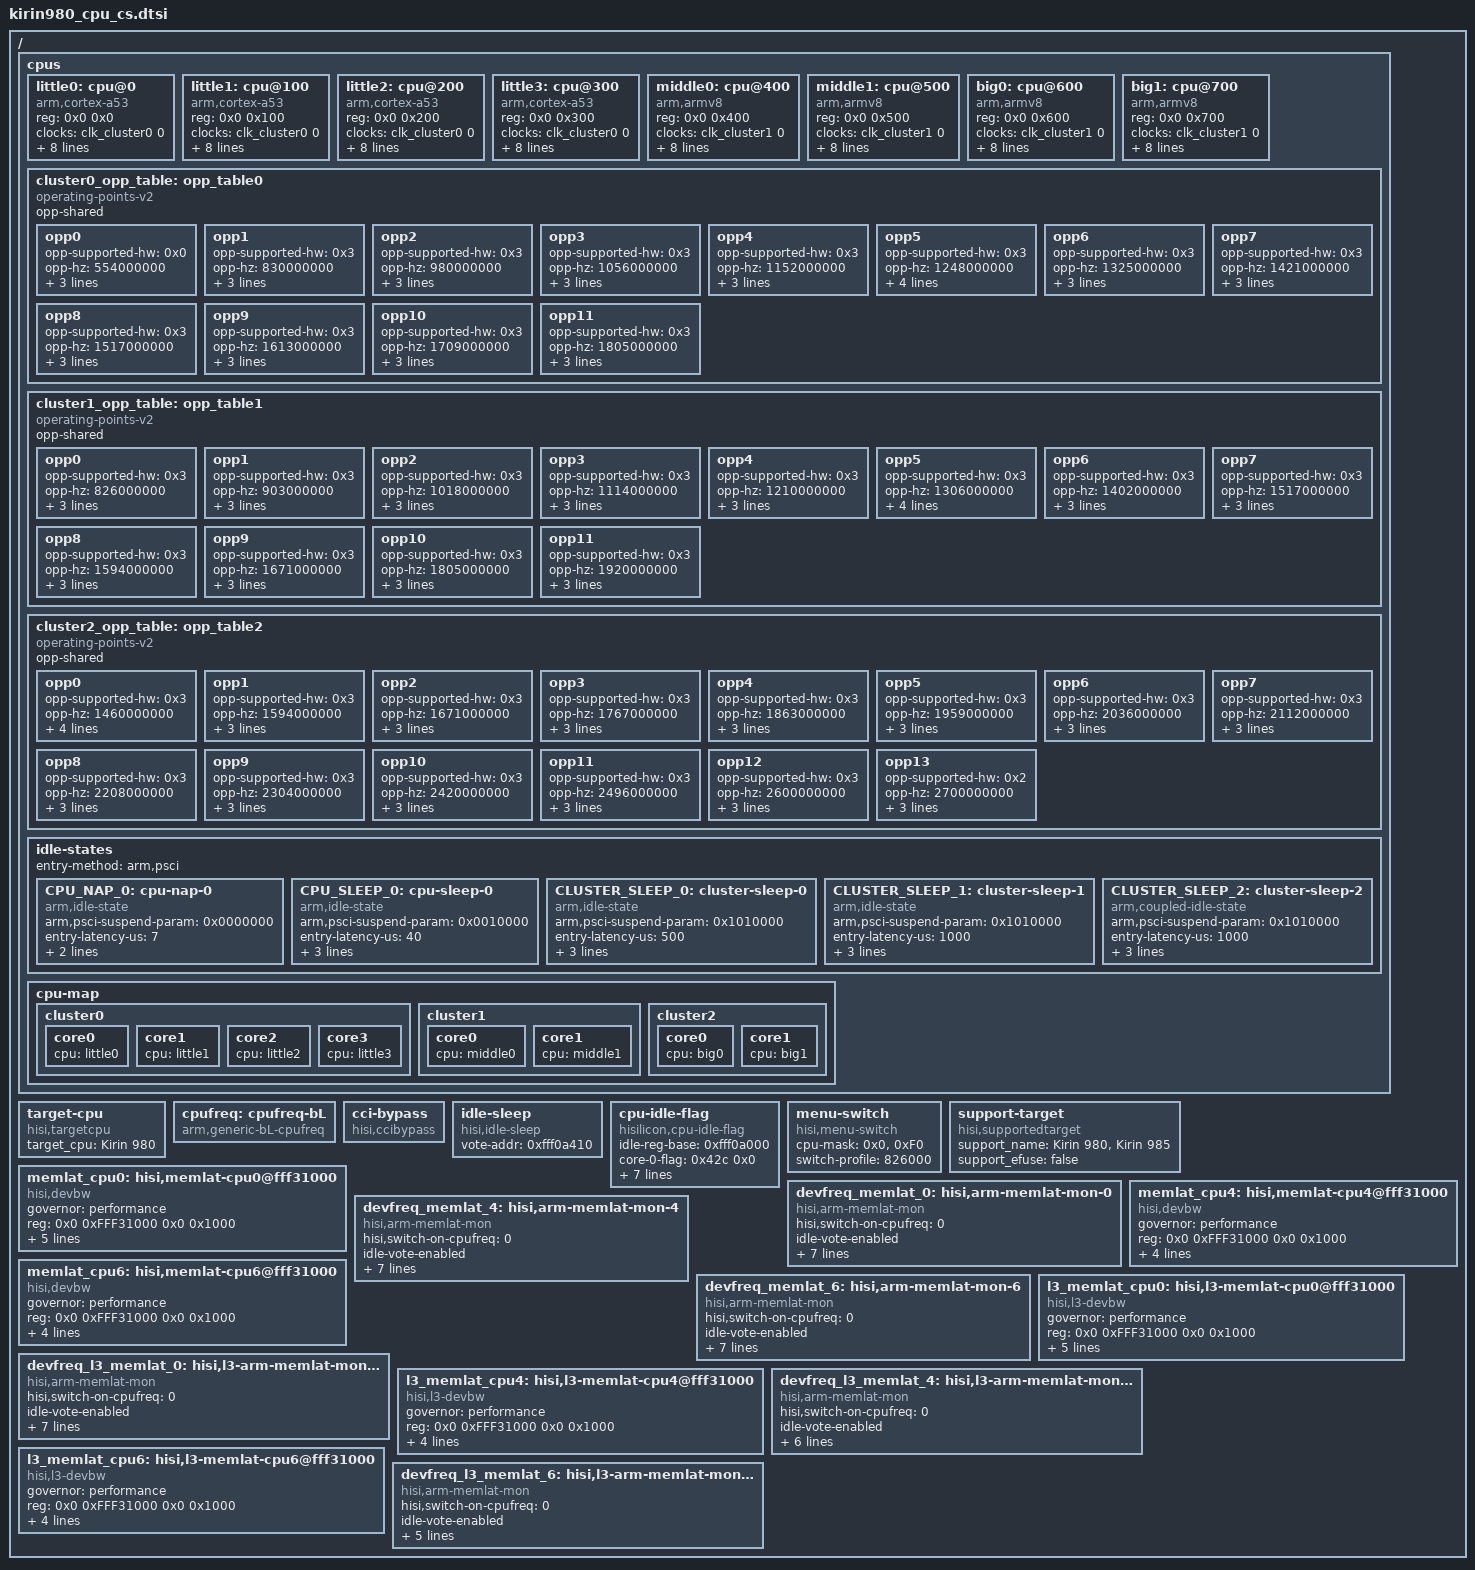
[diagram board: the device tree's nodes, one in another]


/{
	cpus {
		#address-cells = <2>;
		#size-cells = <0>;

		little0: cpu@0 {
			device_type = "cpu";
			compatible = "arm,cortex-a53", "arm,armv8";
			reg = <0x0 0x0>;
			clocks = <&clk_cluster0 0>;
			clock-names = "cpu-cluster.0";
			freq-vote-channel = "little-freq", "vote-src-1";
			enable-method = "psci";
			clock-frequency = <0>;
			clock-latency = <0>;
			cpu-idle-states = <&CPU_SLEEP_0 &CLUSTER_SLEEP_0>;
			operating-points-v2 = <&cluster0_opp_table>;
			sched-energy-costs = <&CPU_COST_Ananke &CLUSTER_COST_Ananke>;
		};
		little1:cpu@100 {
			device_type = "cpu";
			compatible = "arm,cortex-a53", "arm,armv8";
			reg = <0x0 0x100>;
			clocks = <&clk_cluster0 0>;
			clock-names = "cpu-cluster.0";
			freq-vote-channel = "little-freq", "vote-src-1";
			enable-method = "psci";
			clock-frequency = <0>;
			clock-latency = <0>;
			cpu-idle-states = <&CPU_SLEEP_0 &CLUSTER_SLEEP_0>;
			operating-points-v2 = <&cluster0_opp_table>;
			sched-energy-costs = <&CPU_COST_Ananke &CLUSTER_COST_Ananke>;
		};
		little2:cpu@200 {
			device_type = "cpu";
			compatible = "arm,cortex-a53", "arm,armv8";
			reg = <0x0 0x200>;
			clocks = <&clk_cluster0 0>;
			clock-names = "cpu-cluster.0";
			freq-vote-channel = "little-freq", "vote-src-1";
			enable-method = "psci";
			clock-frequency = <0>;
			clock-latency = <0>;
			cpu-idle-states = <&CPU_SLEEP_0 &CLUSTER_SLEEP_0>;
			operating-points-v2 = <&cluster0_opp_table>;
			sched-energy-costs = <&CPU_COST_Ananke &CLUSTER_COST_Ananke>;
		};
		little3:cpu@300 {
			device_type = "cpu";
			compatible = "arm,cortex-a53", "arm,armv8";
			reg = <0x0 0x300>;
			clocks = <&clk_cluster0 0>;
			clock-names = "cpu-cluster.0";
			freq-vote-channel = "little-freq", "vote-src-1";
			enable-method = "psci";
			clock-frequency = <0>;
			clock-latency = <0>;
			cpu-idle-states = <&CPU_SLEEP_0 &CLUSTER_SLEEP_0>;
			operating-points-v2 = <&cluster0_opp_table>;
			sched-energy-costs = <&CPU_COST_Ananke &CLUSTER_COST_Ananke>;
		};


		middle0:cpu@400 {
			device_type = "cpu";
			compatible = "arm,armv8";
			reg = <0x0 0x400>;
			clocks = <&clk_cluster1 0>;
			clock-names = "cpu-cluster.1";
			freq-vote-channel = "middle-freq", "vote-src-1";
			enable-method = "psci";
			clock-frequency = <0>;
			clock-latency = <0>;
			cpu-idle-states = <&CPU_SLEEP_0 &CLUSTER_SLEEP_1>;
			operating-points-v2 = <&cluster1_opp_table>;
			sched-energy-costs = <&CPU_COST_Enyo_M &CLUSTER_COST_Enyo_M>;
		};
		middle1:cpu@500 {
			device_type = "cpu";
			compatible = "arm,armv8";
			reg = <0x0 0x500>;
			clocks = <&clk_cluster1 0>;
			clock-names = "cpu-cluster.1";
			freq-vote-channel = "middle-freq", "vote-src-1";
			clock-frequency = <0>;
			clock-latency = <0>;
			cpu-idle-states = <&CPU_SLEEP_0 &CLUSTER_SLEEP_1>;
			operating-points-v2 = <&cluster1_opp_table>;
			sched-energy-costs = <&CPU_COST_Enyo_M &CLUSTER_COST_Enyo_M>;
			enable-method = "psci";
		};
		big0:cpu@600 {
			device_type = "cpu";
			compatible = "arm,armv8";
			reg = <0x0 0x600>;
			clocks = <&clk_cluster1 0>;
			clock-names = "cpu-cluster.1";
			freq-vote-channel = "big-freq", "vote-src-1";
			clock-frequency = <0>;
			clock-latency = <0>;
			cpu-idle-states = <&CLUSTER_SLEEP_2>;
			operating-points-v2 = <&cluster2_opp_table>;
			sched-energy-costs = <&CPU_COST_Enyo_B &CLUSTER_COST_Enyo_B>;
			enable-method = "psci";
		};
		big1:cpu@700 {
			device_type = "cpu";
			compatible = "arm,armv8";
			reg = <0x0 0x700>;
			clocks = <&clk_cluster1 0>;
			clock-names = "cpu-cluster.1";
			freq-vote-channel = "big-freq", "vote-src-1";
			clock-frequency = <0>;
			clock-latency = <0>;
			cpu-idle-states = <&CLUSTER_SLEEP_2>;
			operating-points-v2 = <&cluster2_opp_table>;
			sched-energy-costs = <&CPU_COST_Enyo_B &CLUSTER_COST_Enyo_B>;
			enable-method = "psci";
		};

		cluster0_opp_table: opp_table0 {
			compatible = "operating-points-v2";
			opp-shared;

			opp0 {
				opp-supported-hw = <0x0>;
				opp-hz = /bits/ 64 <554000000>;
				opp-microvolt = <600000>;
				opp-microamp = <11000>;
				clock-latency-ns = <2000000>;
			};
			opp1 {
				opp-supported-hw = <0x3>;
				opp-hz = /bits/ 64 <830000000>;
				opp-microvolt = <630000>;
				opp-microamp = <17000>;
				clock-latency-ns = <2000000>;
			};
			opp2 {
				opp-supported-hw = <0x3>;
				opp-hz = /bits/ 64 <980000000>;
				opp-microvolt = <700000>;
				opp-microamp = <22000>;
				clock-latency-ns = <2000000>;
			};
			opp3 {
				opp-supported-hw = <0x3>;
				opp-hz = /bits/ 64 <1056000000>;
				opp-microvolt = <700000>;
				opp-microamp = <24000>;
				clock-latency-ns = <2000000>;
			};
			opp4 {
				opp-supported-hw = <0x3>;
				opp-hz = /bits/ 64 <1152000000>;
				opp-microvolt = <700000>;
				opp-microamp = <28000>;
				clock-latency-ns = <2000000>;
			};
			opp5 {
				opp-supported-hw = <0x3>;
				opp-hz = /bits/ 64 <1248000000>;
				opp-microvolt = <700000>;
				opp-microamp = <33000>;
				clock-latency-ns = <2000000>;
				opp-suspend;
			};
			opp6 {
				opp-supported-hw = <0x3>;
				opp-hz = /bits/ 64 <1325000000>;
				opp-microvolt = <800000>;
				opp-microamp = <37000>;
				clock-latency-ns = <2000000>;
			};
			opp7 {
				opp-supported-hw = <0x3>;
				opp-hz = /bits/ 64 <1421000000>;
				opp-microvolt = <800000>;
				opp-microamp = <43000>;
				clock-latency-ns = <2000000>;
			};
			opp8 {
				opp-supported-hw = <0x3>;
				opp-hz = /bits/ 64 <1517000000>;
				opp-microvolt = <800000>;
				opp-microamp = <50000>;
				clock-latency-ns = <2000000>;
			};
			opp9 {
				opp-supported-hw = <0x3>;
				opp-hz = /bits/ 64 <1613000000>;
				opp-microvolt = <800000>;
				opp-microamp = <58000>;
				clock-latency-ns = <2000000>;
			};
			opp10 {
				opp-supported-hw = <0x3>;
				opp-hz = /bits/ 64 <1709000000>;
				opp-microvolt = <900000>;
				opp-microamp = <67000>;
				clock-latency-ns = <2000000>;
			};
			opp11 {
				opp-supported-hw = <0x3>;
				opp-hz = /bits/ 64 <1805000000>;
				opp-microvolt = <900000>;
				opp-microamp = <78000>;
				clock-latency-ns = <2000000>;
			};
		};

		cluster1_opp_table: opp_table1 {
			compatible = "operating-points-v2";
			opp-shared;

			opp0 {
				opp-supported-hw = <0x3>;
				opp-hz = /bits/ 64 <826000000>;
				opp-microvolt = <640000>;
				opp-microamp = <32000>;
				clock-latency-ns = <2000000>;
			};
			opp1 {
				opp-supported-hw = <0x3>;
				opp-hz = /bits/ 64 <903000000>;
				opp-microvolt = <700000>;
				opp-microamp = <35000>;
				clock-latency-ns = <2000000>;
			};
			opp2 {
				opp-supported-hw = <0x3>;
				opp-hz = /bits/ 64 <1018000000>;
				opp-microvolt = <700000>;
				opp-microamp = <41000>;
				clock-latency-ns = <2000000>;
			};
			opp3 {
				opp-supported-hw = <0x3>;
				opp-hz = /bits/ 64 <1114000000>;
				opp-microvolt = <700000>;
				opp-microamp = <48000>;
				clock-latency-ns = <2000000>;
			};
			opp4 {
				opp-supported-hw = <0x3>;
				opp-hz = /bits/ 64 <1210000000>;
				opp-microvolt = <700000>;
				opp-microamp = <55000>;
				clock-latency-ns = <2000000>;
			};
			opp5 {
				opp-supported-hw = <0x3>;
				opp-hz = /bits/ 64 <1306000000>;
				opp-microvolt = <700000>;
				opp-microamp = <62000>;
				clock-latency-ns = <2000000>;
				opp-suspend;
			};
			opp6 {
				opp-supported-hw = <0x3>;
				opp-hz = /bits/ 64 <1402000000>;
				opp-microvolt = <800000>;
				opp-microamp = <71000>;
				clock-latency-ns = <2000000>;
			};
			opp7 {
				opp-supported-hw = <0x3>;
				opp-hz = /bits/ 64 <1517000000>;
				opp-microvolt = <800000>;
				opp-microamp = <84000>;
				clock-latency-ns = <2000000>;
			};
			opp8 {
				opp-supported-hw = <0x3>;
				opp-hz = /bits/ 64 <1594000000>;
				opp-microvolt = <800000>;
				opp-microamp = <95000>;
				clock-latency-ns = <2000000>;
			};
			opp9 {
				opp-supported-hw = <0x3>;
				opp-hz = /bits/ 64 <1671000000>;
				opp-microvolt = <800000>;
				opp-microamp = <105000>;
				clock-latency-ns = <2000000>;
			};
			opp10 {
				opp-supported-hw = <0x3>;
				opp-hz = /bits/ 64 <1805000000>;
				opp-microvolt = <900000>;
				opp-microamp = <127000>;
				clock-latency-ns = <2000000>;
			};
			opp11 {
				opp-supported-hw = <0x3>;
				opp-hz = /bits/ 64 <1920000000>;
				opp-microvolt = <900000>;
				opp-microamp = <145000>;
				clock-latency-ns = <2000000>;
			};
		};

		cluster2_opp_table: opp_table2 {
			compatible = "operating-points-v2";
			opp-shared;

			opp0 {
				opp-supported-hw = <0x3>;
				opp-hz = /bits/ 64 <1460000000>;
				opp-microvolt = <700000>;
				opp-microamp = <98000>;
				clock-latency-ns = <2000000>;
				opp-suspend;
			};
			opp1 {
				opp-supported-hw = <0x3>;
				opp-hz = /bits/ 64 <1594000000>;
				opp-microvolt = <800000>;
				opp-microamp = <118000>;
				clock-latency-ns = <2000000>;
			};
			opp2 {
				opp-supported-hw = <0x3>;
				opp-hz = /bits/ 64 <1671000000>;
				opp-microvolt = <800000>;
				opp-microamp = <145000>;
				clock-latency-ns = <2000000>;
			};
			opp3 {
				opp-supported-hw = <0x3>;
				opp-hz = /bits/ 64 <1767000000>;
				opp-microvolt = <800000>;
				opp-microamp = <166000>;
				clock-latency-ns = <2000000>;
			};
			opp4 {
				opp-supported-hw = <0x3>;
				opp-hz = /bits/ 64 <1863000000>;
				opp-microvolt = <800000>;
				opp-microamp = <192000>;
				clock-latency-ns = <2000000>;
			};
			opp5 {
				opp-supported-hw = <0x3>;
				opp-hz = /bits/ 64 <1959000000>;
				opp-microvolt = <800000>;
				opp-microamp = <220000>;
				clock-latency-ns = <2000000>;
			};
			opp6 {
				opp-supported-hw = <0x3>;
				opp-hz = /bits/ 64 <2036000000>;
				opp-microvolt = <800000>;
				opp-microamp = <244000>;
				clock-latency-ns = <2000000>;
			};
			opp7 {
				opp-supported-hw = <0x3>;
				opp-hz = /bits/ 64 <2112000000>;
				opp-microvolt = <900000>;
				opp-microamp = <270000>;
				clock-latency-ns = <2000000>;
			};
			opp8 {
				opp-supported-hw = <0x3>;
				opp-hz = /bits/ 64 <2208000000>;
				opp-microvolt = <900000>;
				opp-microamp = <310000>;
				clock-latency-ns = <2000000>;
			};
			opp9 {
				opp-supported-hw = <0x3>;
				opp-hz = /bits/ 64 <2304000000>;
				opp-microvolt = <900000>;
				opp-microamp = <355000>;
				clock-latency-ns = <2000000>;
			};
			opp10 {
				opp-supported-hw = <0x3>;
				opp-hz = /bits/ 64 <2420000000>;
				opp-microvolt = <1000000>;
				opp-microamp = <418000>;
				clock-latency-ns = <2000000>;
			};
			opp11 {
				opp-supported-hw = <0x3>;
				opp-hz = /bits/ 64 <2496000000>;
				opp-microvolt = <1010000>;
				opp-microamp = <468000>;
				clock-latency-ns = <2000000>;
			};
			opp12 {
				opp-supported-hw = <0x3>;
				opp-hz = /bits/ 64 <2600000000>;
				opp-microvolt = <1050000>;
				opp-microamp = <545000>;
				clock-latency-ns = <2000000>;
			};
			opp13 {
				opp-supported-hw = <0x2>;
				opp-hz = /bits/ 64 <2700000000>;
				opp-microvolt = <1050000>;
				opp-microamp = <609000>;
				clock-latency-ns = <2000000>;
			};
		};

		idle-states {
			entry-method = "arm,psci";

			CPU_NAP_0: cpu-nap-0 {
				compatible = "arm,idle-state";
				arm,psci-suspend-param = <0x0000000>;
				entry-latency-us = <7>;
				exit-latency-us = <2>;
				min-residency-us = <15>;
			};

			CPU_SLEEP_0: cpu-sleep-0 {
				compatible = "arm,idle-state";
				arm,psci-suspend-param = <0x0010000>;
				entry-latency-us = <40>;
				exit-latency-us = <70>;
				min-residency-us = <3000>;
				local-timer-stop;
			};

			CLUSTER_SLEEP_0: cluster-sleep-0 {
				compatible = "arm,idle-state";
				arm,psci-suspend-param = <0x1010000>;
				entry-latency-us = <500>;
				exit-latency-us = <5000>;
				min-residency-us = <20000>;
				local-timer-stop;
			};
			CLUSTER_SLEEP_1: cluster-sleep-1 {
				compatible = "arm,idle-state";
				arm,psci-suspend-param = <0x1010000>;
				entry-latency-us = <1000>;
				exit-latency-us = <5000>;
				min-residency-us = <20000>;
				local-timer-stop;
			};
			CLUSTER_SLEEP_2: cluster-sleep-2 {
				compatible = "arm,coupled-idle-state";
				arm,psci-suspend-param = <0x1010000>;
				entry-latency-us = <1000>;
				exit-latency-us = <5000>;
				min-residency-us = <20000>;
				local-timer-stop;
			};
		};

		cpu-map {
			cluster0: cluster0 {
				#cooling-cells = <3>; /* min followed by max */
				core0 {
					cpu = <&little0>;
				};
				core1 {
					cpu = <&little1>;
				};
				core2 {
					cpu = <&little2>;
				};
				core3 {
					cpu = <&little3>;
				};
			};
			cluster1: cluster1 {
				#cooling-cells = <2>; /* min followed by max */
				core0 {
					cpu = <&middle0>;
				};
				core1 {
					cpu = <&middle1>;
				};
			};
			cluster2: cluster2 {
				#cooling-cells = <2>; /* min followed by max */
				core0 {
					cpu = <&big0>;
				};
				core1 {
					cpu = <&big1>;
				};
			};
		};
		/include/ "kirin980_sched_energy_cs.dtsi"
	};

	target-cpu {
		compatible = "hisi,targetcpu";
		target_cpu = "Kirin 980";
	};

	/* cpufreq  device */
	cpufreq: cpufreq-bL {
		compatible = "arm,generic-bL-cpufreq";
		status = "ok";
	};

	cci-bypass {
		compatible = "hisi,ccibypass";
		status = "ok";
	};

	idle-sleep {
		compatible = "hisi,idle-sleep";
		vote-addr = <0xfff0a410>;
		status = "ok";
	};

	cpu-idle-flag {
		compatible = "hisilicon,cpu-idle-flag";
		idle-reg-base = <0xfff0a000>;
		core-0-flag = <0x42c 0x0>; /* SOC_SCTRL_SCBAKDATA8_ADDR */
		core-1-flag = <0x42c 0x1>; /* SOC_SCTRL_SCBAKDATA8_ADDR */
		core-2-flag = <0x42c 0x2>; /* SOC_SCTRL_SCBAKDATA8_ADDR */
		core-3-flag = <0x42c 0x3>; /* SOC_SCTRL_SCBAKDATA8_ADDR */
		core-4-flag = <0x42c 0x4>; /* SOC_SCTRL_SCBAKDATA8_ADDR */
		core-5-flag = <0x42c 0x5>; /* SOC_SCTRL_SCBAKDATA8_ADDR */
		core-6-flag = <0x42c 0x6>; /* SOC_SCTRL_SCBAKDATA8_ADDR */
		core-7-flag = <0x42c 0x7>; /* SOC_SCTRL_SCBAKDATA8_ADDR */
	};

	menu-switch {
		compatible = "hisi,menu-switch";
		cpu-mask = <0x0>, <0xF0>;
		switch-profile = <826000>;
	};

	support-target {
		compatible = "hisi,supportedtarget";
		support_name = "Kirin 980","Kirin 985";
		support_efuse = "false";
	};

	memlat_cpu0: hisi,memlat-cpu0@fff31000 {
		compatible = "hisi,devbw";
		#address-cells = <2>;
		#size-cells=<2>;
		governor = "performance";
		reg = <0x0 0xFFF31000 0x0 0x1000>;
		hisi,vote-reg = <0x2b8 0xFF>;
		hisi,cpulist =	<&little0 &little1 &little2 &little3>;
		hisi,freq-tbl =
			<  237  /*  237 MHz */ >,
			<  415  /*  415 MHz */ >,
			<  673  /*  673 MHz */ >,
			<  830  /*  830 MHz */ >,
			<  1244 /*  1244 MHz */ >,
			<  1660 /*  1660 MHz */ >,
			<  1866 /*  1866 MHz */ >,
			<  2133 /*  2133 MHz */ >;
	};

	devfreq_memlat_0: hisi,arm-memlat-mon-0 {
		compatible = "hisi,arm-memlat-mon";
		hisi,switch-on-cpufreq = <0>;
		idle-vote-enabled;
		hisi,cachemiss-ev = <0x2A>;
		hisi,cpulist =	<&little0 &little1 &little2 &little3>;
		hisi,target-dev = <&memlat_cpu0>;
		hisi,core-dev-table =
			<  554000  237 >,
			<  830000  237 >,
			<  980000  415 >,
			< 1152000  415 >,
			< 1248000 673 >,
			< 1613000 673 >,
			< 1709000 830 >,
			< 1805000 830 >;
	};

	memlat_cpu4: hisi,memlat-cpu4@fff31000 {
		compatible = "hisi,devbw";
		#address-cells = <2>;
		#size-cells=<2>;
		governor = "performance";
		reg = <0x0 0xFFF31000 0x0 0x1000>;
		hisi,vote-reg = <0x2b8 0xFF00>;
		hisi,cpulist =	<&middle0 &middle1>;
		hisi,freq-tbl =
			<  237  /*  237 MHz */ >,
			<  415  /*  415 MHz */ >,
			<  673  /*  673 MHz */ >,
			<  830  /*  830 MHz */ >,
			<  1244 /*  1244 MHz */ >,
			<  1660 /*  1660 MHz */ >,
			<  1866 /*  1866 MHz */ >,
			<  2133 /*  2133 MHz */ >;
	};

	devfreq_memlat_4: hisi,arm-memlat-mon-4 {
		compatible = "hisi,arm-memlat-mon";
		hisi,switch-on-cpufreq = <0>;
		idle-vote-enabled;
		hisi,cachemiss-ev = <0x2A>;
		hisi,cpulist =	<&middle0 &middle1>;
		hisi,target-dev = <&memlat_cpu4>;
		hisi,core-dev-table =
			< 700000  237 >,
			< 826000  415 >,
			< 1018000  415 >,
			< 1114000  673 >,
			< 1210000 673 >,
			< 1306000 830 >,
			< 1517000 830 >,
			< 1594000 1244 >,
			< 1805000 1244 >,
			< 1920000 1660 >,
			< 2093000 1660 >;
	};

	memlat_cpu6: hisi,memlat-cpu6@fff31000 {
		compatible = "hisi,devbw";
		#address-cells = <2>;
		#size-cells=<2>;
		governor = "performance";
		reg = <0x0 0xFFF31000 0x0 0x1000>;
		hisi,vote-reg = <0x2bc 0xFF>;
		hisi,cpulist =	<&big0 &big1>;
		hisi,freq-tbl =
			<  237  /*  237 MHz */ >,
			<  415  /*  415 MHz */ >,
			<  673  /*  673 MHz */ >,
			<  830  /*  830 MHz */ >,
			<  1244 /*  1244 MHz */ >,
			<  1660 /*  1660 MHz */ >,
			<  1866 /*  1866 MHz */ >,
			<  2133 /*  2133 MHz */ >;
	};

	devfreq_memlat_6: hisi,arm-memlat-mon-6 {
		compatible = "hisi,arm-memlat-mon";
		hisi,switch-on-cpufreq = <0>;
		idle-vote-enabled;
		hisi,cachemiss-ev = <0x2A>;
		hisi,cpulist =	<&big0 &big1>;
		hisi,target-dev = <&memlat_cpu6>;
		hisi,core-dev-table =
			<  800000  237 >,
			< 1460000 830 >,
			< 1671000 830 >,
			< 1767000 1244 >,
			< 1959000 1244 >,
			< 2036000 1600 >,
			< 2420000 1600 >,
			< 2516000 1866 >,
			< 2700000 2133 >;
	};

	l3_memlat_cpu0: hisi,l3-memlat-cpu0@fff31000 {
		compatible = "hisi,l3-devbw";
		#address-cells = <2>;
		#size-cells=<2>;
		governor = "performance";
		reg = <0x0 0xFFF31000 0x0 0x1000>;
		hisi,vote-reg = <0x250 0xFF00>;
		hisi,cpulist =	<&little0 &little1 &little2 &little3>;
		hisi,freq-tbl =
			<  554  /*  554 MHz */ >,
			<  830  /*  830 MHz */ >,
			<  907  /*  907 MHz */ >,
			<  999  /*  999 MHz */ >,
			<  1095  /* 1095 MHz */ >,
			<  1191 /*  1191 MHz */ >,
			<  1287 /*  1287 MHz */ >,
			<  1632 /*  1632 MHz */ >;
	};

	devfreq_l3_memlat_0: hisi,l3-arm-memlat-mon-0 {
		compatible = "hisi,arm-memlat-mon";
		hisi,switch-on-cpufreq = <0>;
		idle-vote-enabled;
		hisi,cachemiss-ev = <0x17>;
		hisi,cpulist =	<&little0 &little1 &little2 &little3>;
		hisi,target-dev = <&l3_memlat_cpu0>;
		hisi,core-dev-table =
			<  554000  554 >,
			<  830000  554 >,
			<  980000  830 >,
			< 1248000 830 >,
			< 1325000 999 >,
			< 1613000 999 >,
			< 1709000 1632 >,
			< 1805000 1632 >;
	};

	l3_memlat_cpu4: hisi,l3-memlat-cpu4@fff31000 {
		compatible = "hisi,l3-devbw";
		#address-cells = <2>;
		#size-cells=<2>;
		governor = "performance";
		reg = <0x0 0xFFF31000 0x0 0x1000>;
		hisi,vote-reg = <0x254 0xFF>;
		hisi,cpulist =	<&middle0 &middle1>;
		hisi,freq-tbl =
			<  554  /*  554 MHz */ >,
			<  830  /*  830 MHz */ >,
			<  907  /*  907 MHz */ >,
			<  999  /*  999 MHz */ >,
			<  1095  /* 1095 MHz */ >,
			<  1191 /*  1191 MHz */ >,
			<  1287 /*  1287 MHz */ >,
			<  1632 /*  1632 MHz */ >;
	};

	devfreq_l3_memlat_4: hisi,l3-arm-memlat-mon-4 {
		compatible = "hisi,arm-memlat-mon";
		hisi,switch-on-cpufreq = <0>;
		idle-vote-enabled;
		hisi,cachemiss-ev = <0x17>;
		hisi,cpulist =	<&middle0 &middle1>;
		hisi,target-dev = <&l3_memlat_cpu4>;
		hisi,core-dev-table =
			<  700000  554 >,
			<  826000  907 >,
			< 903000  1095 >,
			< 1306000 1095 >,
			< 1402000 1287 >,
			< 1671000 1287 >,
			< 1805000 1632 >,
			< 2093000 1632 >;
	};

	l3_memlat_cpu6: hisi,l3-memlat-cpu6@fff31000 {
		compatible = "hisi,l3-devbw";
		#address-cells = <2>;
		#size-cells=<2>;
		governor = "performance";
		reg = <0x0 0xFFF31000 0x0 0x1000>;
		hisi,vote-reg = <0x254 0xFF00>;
		hisi,cpulist =	<&big0 &big1>;
		hisi,freq-tbl =
			<  554  /*  554 MHz */ >,
			<  830  /*  830 MHz */ >,
			<  907  /*  907 MHz */ >,
			<  999  /*  999 MHz */ >,
			<  1095  /* 1095 MHz */ >,
			<  1191 /*  1191 MHz */ >,
			<  1287 /*  1287 MHz */ >,
			<  1632 /*  1632 MHz */ >;
	};

	devfreq_l3_memlat_6: hisi,l3-arm-memlat-mon-6 {
		compatible = "hisi,arm-memlat-mon";
		hisi,switch-on-cpufreq = <0>;
		idle-vote-enabled;
		hisi,cachemiss-ev = <0x17>;
		hisi,cpulist =	<&big0 &big1>;
		hisi,target-dev = <&l3_memlat_cpu6>;
		hisi,core-dev-table =
			< 800000  554 >,
			< 1460000 1287 >,
			< 2516000 1287 >,
			< 2700000 1632 >;
	};
};
